# STM32MP157 register map
File version: 1.6
CPU: CM4 r0p1, little endian, no MPU, FPU, 4 interrupt priority bits
Registers are 32-bit, read-write, reset 0x0 unless marked. A register's access mark holds for its fields unless they carry their own. Offsets are from the block's base; [hi:lo] are bit positions; {n}, {i} and the like mark numbered series.

## ADC
Base 0x48003000
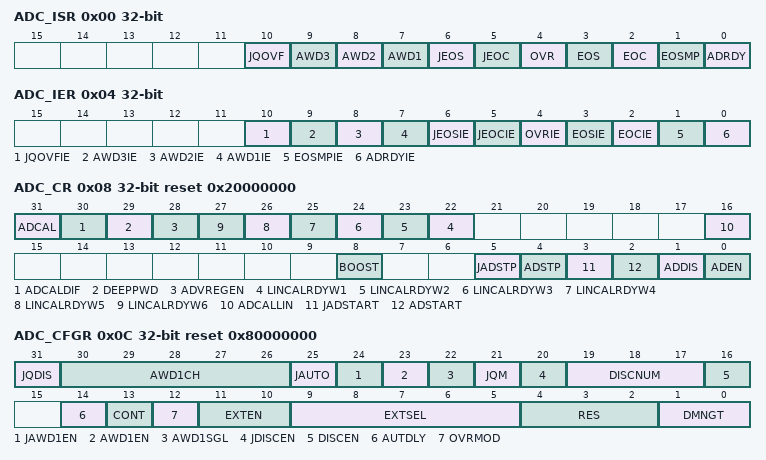
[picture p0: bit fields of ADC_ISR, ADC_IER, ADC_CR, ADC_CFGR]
0x00 ADC_ISR — ADC interrupt and status register
  [10] JQOVF, [9] AWD3, [8] AWD2, [7] AWD1, [6] JEOS, [5] JEOC, [4] OVR, [3] EOS, [2] EOC, [1] EOSMP, [0] ADRDY
0x04 ADC_IER — ADC interrupt enable register
  [10] JQOVFIE, [9] AWD3IE, [8] AWD2IE, [7] AWD1IE, [6] JEOSIE, [5] JEOCIE, [4] OVRIE, [3] EOSIE, [2] EOCIE, [1] EOSMPIE, [0] ADRDYIE
0x08 ADC_CR reset 0x20000000 — ADC control register
  [31] ADCAL, [30] ADCALDIF, [29] DEEPPWD, [28] ADVREGEN, [n+21] LINCALRDYW{n} (n=1..6), [16] ADCALLIN, [8] BOOST, [5] JADSTP, [4] ADSTP, [3] JADSTART, [2] ADSTART, [1] ADDIS, [0] ADEN
0x0C ADC_CFGR reset 0x80000000 — ADC configuration register
  [31] JQDIS, [30:26] AWD1CH, [25] JAUTO, [24] JAWD1EN, [23] AWD1EN, [22] AWD1SGL, [21] JQM, [20] JDISCEN, [19:17] DISCNUM, [16] DISCEN, [14] AUTDLY, [13] CONT, [12] OVRMOD, [11:10] EXTEN, [9:5] EXTSEL, [4:2] RES, [1:0] DMNGT
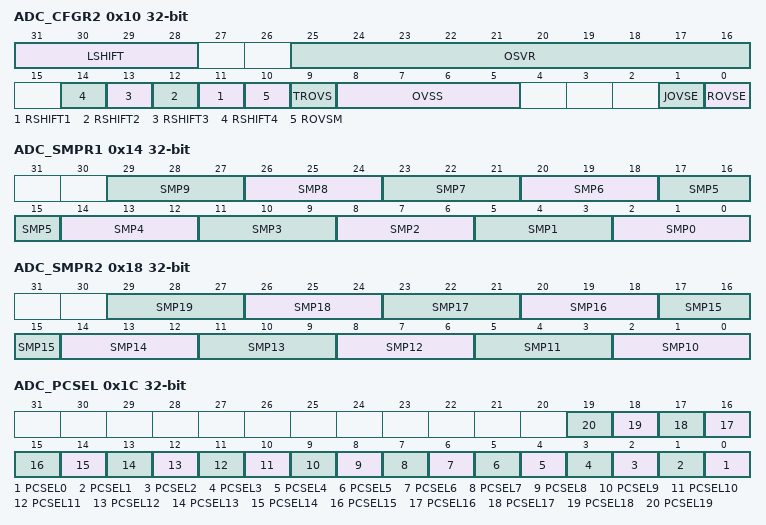
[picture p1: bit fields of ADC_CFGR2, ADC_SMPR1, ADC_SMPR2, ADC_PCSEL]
0x10 ADC_CFGR2 — ADC configuration register 2
  [31:28] LSHIFT, [25:16] OSVR, [n+10] RSHIFT{n} (n=1..4), [10] ROVSM, [9] TROVS, [8:5] OVSS, [1] JOVSE, [0] ROVSE
0x14 ADC_SMPR1 — ADC sample time register 1
  [3n+2:3n] SMP{n} (n=0..9)
0x18 ADC_SMPR2 — ADC sample time register 2
  [3n-28:3n-30] SMP{n} (n=10..19)
0x1C ADC_PCSEL — ADC channel preselection register
  [n] PCSEL{n} (n=0..19)
0x20 ADC_LTR1 — ADC watchdog threshold register 1
  [25:0] LTR1
0x24 ADC_HTR1 reset 0x3FFFFFF — ADC watchdog threshold register 1
  [25:0] HTR1
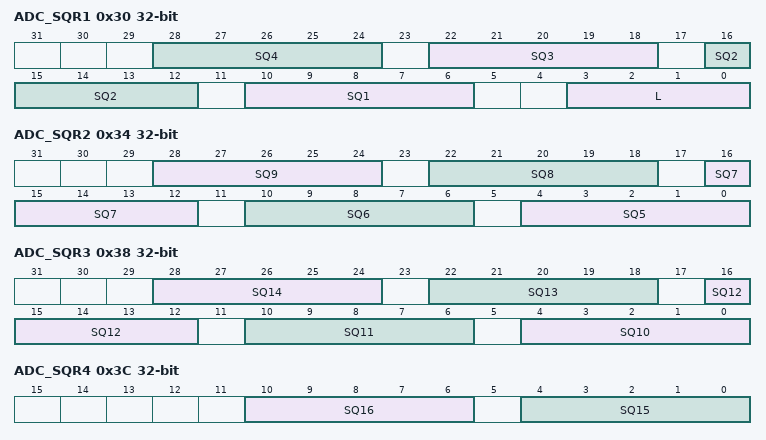
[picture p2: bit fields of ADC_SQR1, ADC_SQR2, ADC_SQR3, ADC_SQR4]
0x30 ADC_SQR1 — ADC regular sequence register 1
  [6n+4:6n] SQ{n} (n=1..4), [3:0] L
0x34 ADC_SQR2 — ADC regular sequence register 2
  [6n-26:6n-30] SQ{n} (n=5..9)
0x38 ADC_SQR3 — ADC regular sequence register 3
  [6n-56:6n-60] SQ{n} (n=10..14)
0x3C ADC_SQR4 — ADC regular sequence register 4
  [10:6] SQ16, [4:0] SQ15
0x40 ADC_DR ro — ADC regular Data Register
  [31:0] RDATA
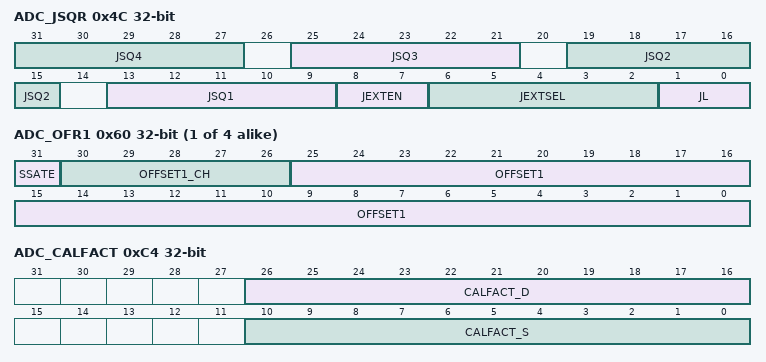
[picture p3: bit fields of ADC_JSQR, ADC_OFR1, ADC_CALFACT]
0x4C ADC_JSQR — ADC injected sequence register
  [6n+7:6n+3] JSQ{n} (n=1..4), [8:7] JEXTEN, [6:2] JEXTSEL, [1:0] JL
{0x5C+4i} ADC_OFR{i} (i=1..4) — ADC offset register
  [31] SSATE, [30:26] OFFSET{i}_CH, [25:0] OFFSET{i}
{0x7C+4i} ADC_JDR{i} ro (i=1..4) — ADC injected data register
  [31:0] JDATA
0xA0 ADC_AWD2CR — ADC analog watchdog 2 configuration register
  [19:0] AWD2CH
0xA4 ADC_AWD3CR — ADC analog watchdog 3 configuration register
  [19:0] AWD3CH
0xB0 ADC_LTR2 — ADC watchdog lower threshold register 2
  [25:0] LTR2
0xB4 ADC_HTR2 reset 0x3FFFFFF — ADC watchdog higher threshold register 2
  [25:0] HTR2
0xB8 ADC_LTR3 — ADC watchdog lower threshold register 3
  [25:0] LTR3
0xBC ADC_HTR3 reset 0x3FFFFFF — ADC watchdog higher threshold register 3
  [25:0] HTR3
0xC0 ADC_DIFSEL — ADC differential mode selection register
  [19:0] DIFSEL
0xC4 ADC_CALFACT — ADC calibration factors register
  [26:16] CALFACT_D, [10:0] CALFACT_S
0xC8 ADC_CALFACT2 — ADC calibration factor register 2
  [29:0] LINCALFACT

## ADC2
Base 0x48003100
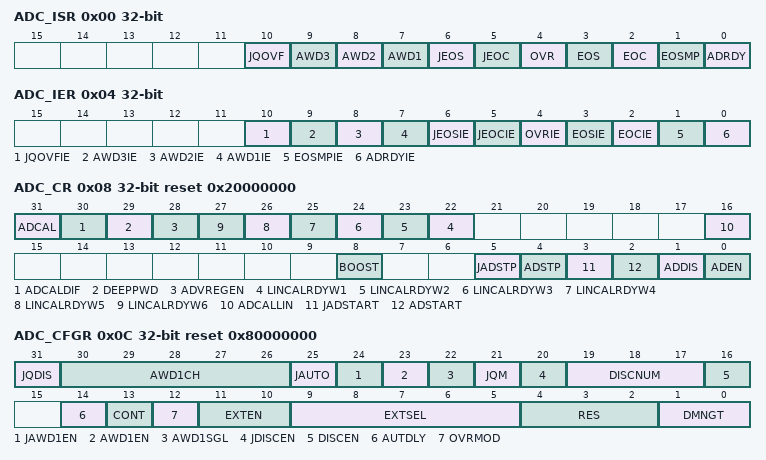
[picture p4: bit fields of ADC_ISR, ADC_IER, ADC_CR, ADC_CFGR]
0x00 ADC_ISR — ADC interrupt and status register
  [10] JQOVF, [9] AWD3, [8] AWD2, [7] AWD1, [6] JEOS, [5] JEOC, [4] OVR, [3] EOS, [2] EOC, [1] EOSMP, [0] ADRDY
0x04 ADC_IER — ADC interrupt enable register
  [10] JQOVFIE, [9] AWD3IE, [8] AWD2IE, [7] AWD1IE, [6] JEOSIE, [5] JEOCIE, [4] OVRIE, [3] EOSIE, [2] EOCIE, [1] EOSMPIE, [0] ADRDYIE
0x08 ADC_CR reset 0x20000000 — ADC control register
  [31] ADCAL, [30] ADCALDIF, [29] DEEPPWD, [28] ADVREGEN, [n+21] LINCALRDYW{n} (n=1..6), [16] ADCALLIN, [8] BOOST, [5] JADSTP, [4] ADSTP, [3] JADSTART, [2] ADSTART, [1] ADDIS, [0] ADEN
0x0C ADC_CFGR reset 0x80000000 — ADC configuration register
  [31] JQDIS, [30:26] AWD1CH, [25] JAUTO, [24] JAWD1EN, [23] AWD1EN, [22] AWD1SGL, [21] JQM, [20] JDISCEN, [19:17] DISCNUM, [16] DISCEN, [14] AUTDLY, [13] CONT, [12] OVRMOD, [11:10] EXTEN, [9:5] EXTSEL, [4:2] RES, [1:0] DMNGT
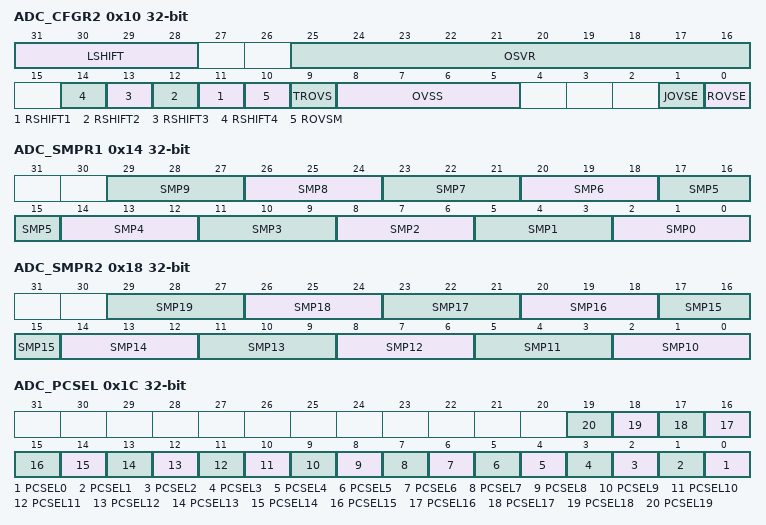
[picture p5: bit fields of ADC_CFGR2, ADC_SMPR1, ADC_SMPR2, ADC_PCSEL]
0x10 ADC_CFGR2 — ADC configuration register 2
  [31:28] LSHIFT, [25:16] OSVR, [n+10] RSHIFT{n} (n=1..4), [10] ROVSM, [9] TROVS, [8:5] OVSS, [1] JOVSE, [0] ROVSE
0x14 ADC_SMPR1 — ADC sample time register 1
  [3n+2:3n] SMP{n} (n=0..9)
0x18 ADC_SMPR2 — ADC sample time register 2
  [3n-28:3n-30] SMP{n} (n=10..19)
0x1C ADC_PCSEL — ADC channel preselection register
  [n] PCSEL{n} (n=0..19)
0x20 ADC_LTR1 — ADC watchdog threshold register 1
  [25:0] LTR1
0x24 ADC_HTR1 reset 0x3FFFFFF — ADC watchdog threshold register 1
  [25:0] HTR1
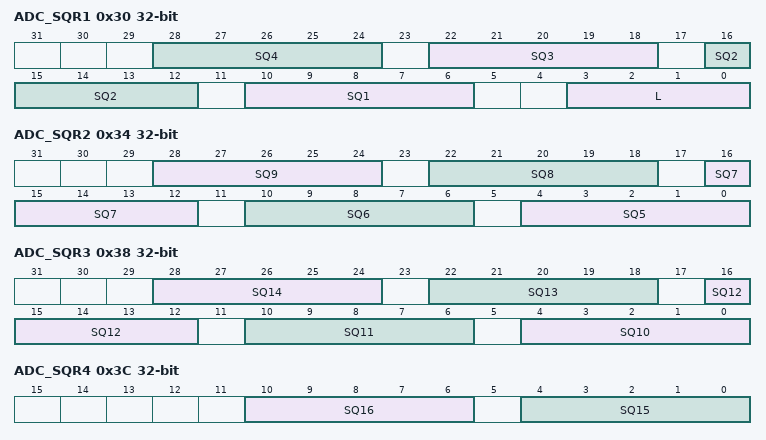
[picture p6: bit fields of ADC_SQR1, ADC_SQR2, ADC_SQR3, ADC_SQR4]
0x30 ADC_SQR1 — ADC regular sequence register 1
  [6n+4:6n] SQ{n} (n=1..4), [3:0] L
0x34 ADC_SQR2 — ADC regular sequence register 2
  [6n-26:6n-30] SQ{n} (n=5..9)
0x38 ADC_SQR3 — ADC regular sequence register 3
  [6n-56:6n-60] SQ{n} (n=10..14)
0x3C ADC_SQR4 — ADC regular sequence register 4
  [10:6] SQ16, [4:0] SQ15
0x40 ADC_DR ro — ADC regular Data Register
  [31:0] RDATA
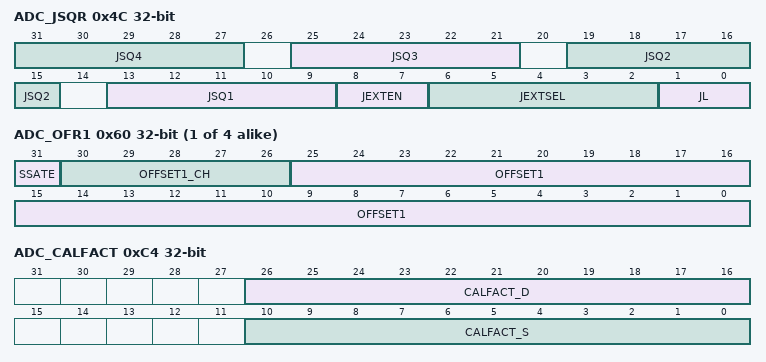
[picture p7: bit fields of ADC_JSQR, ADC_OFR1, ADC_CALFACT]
0x4C ADC_JSQR — ADC injected sequence register
  [6n+7:6n+3] JSQ{n} (n=1..4), [8:7] JEXTEN, [6:2] JEXTSEL, [1:0] JL
{0x5C+4i} ADC_OFR{i} (i=1..4) — ADC offset register
  [31] SSATE, [30:26] OFFSET{i}_CH, [25:0] OFFSET{i}
{0x7C+4i} ADC_JDR{i} ro (i=1..4) — ADC injected data register
  [31:0] JDATA
0xA0 ADC_AWD2CR — ADC analog watchdog 2 configuration register
  [19:0] AWD2CH
0xA4 ADC_AWD3CR — ADC analog watchdog 3 configuration register
  [19:0] AWD3CH
0xB0 ADC_LTR2 — ADC watchdog lower threshold register 2
  [25:0] LTR2
0xB4 ADC_HTR2 reset 0x3FFFFFF — ADC watchdog higher threshold register 2
  [25:0] HTR2
0xB8 ADC_LTR3 — ADC watchdog lower threshold register 3
  [25:0] LTR3
0xBC ADC_HTR3 reset 0x3FFFFFF — ADC watchdog higher threshold register 3
  [25:0] HTR3
0xC0 ADC_DIFSEL — ADC differential mode selection register
  [19:0] DIFSEL
0xC4 ADC_CALFACT — ADC calibration factors register
  [26:16] CALFACT_D, [10:0] CALFACT_S
0xC8 ADC_CALFACT2 — ADC calibration factor register 2
  [29:0] LINCALFACT
0xD0 ADC2_OR — ADC2 option register
  [0] VDDCOREEN
